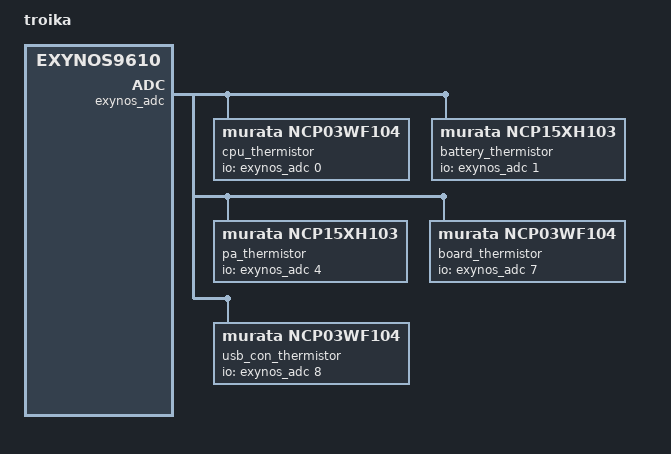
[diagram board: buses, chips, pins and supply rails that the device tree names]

/ {
	fragment@model {
		target-path = "/";
		__overlay__ {
			model = "troika";
			mot,soc-id = <0xE9610000>;
			mot,board-id = <0x43 0xA100>;

			utags {
				compatible = "mmi,utags";
				mmi,main-utags = "/dev/block/bootdevice/by-name/utags";
				mmi,backup-utags = "/dev/block/bootdevice/by-name/utagsBackup";
			};

			hw {
				compatible = "mmi,utags";
				mmi,dir-name = "hw";
				mmi,main-utags = "/dev/block/bootdevice/by-name/hw";
			};

			aov-trigger {
				status = "okay";
				compatible = "mmi,aov-trigger";
			};

		};
	};
};

&exynos_adc {
	status = "okay";
	cpu_thermistor {
		compatible = "murata,ncp03wf104";
		status = "okay";
		pullup-uv = <1800000>;
		pullup-ohm = <100000>;
		pulldown-ohm = <0>;
		io-channels = <&exynos_adc 0>;
		io-channel-names = "cpu_therm";
	};
	battery_thermistor {
		compatible = "murata,ncp15xh103";
		status = "okay";
		pullup-uv = <1800000>;
		pullup-ohm = <100000>;
		pulldown-ohm = <0>;
		io-channels = <&exynos_adc 1>;
		io-channel-names = "bat_therm";
	};
	pa_thermistor {
		compatible = "murata,ncp15xh103";
		status = "okay";
		pullup-uv = <1800000>;
		pullup-ohm = <0>;
		pulldown-ohm = <10000>;
		io-channels = <&exynos_adc 4>;
		io-channel-names = "pa_therm";
		connected-positive;
	};
	board_thermistor {
		compatible = "murata,ncp03wf104";
		status = "okay";
		pullup-uv = <1800000>;
		pullup-ohm = <100000>;
		pulldown-ohm = <0>;
		io-channels = <&exynos_adc 7>;
		io-channel-names = "board_therm";
	};
	usb_con_thermistor {
		compatible = "murata,ncp03wf104";
		status = "okay";
		pullup-uv = <1800000>;
		pullup-ohm = <100000>;
		pulldown-ohm = <0>;
		io-channels = <&exynos_adc 8>;
		io-channel-names = "usb_con_therm";
	};
};

&sar_sx933x {
		Semtech,reg-init = <
		0x8020 0x1F0000
		0x4004 0x64
		0x4008 0x00
		0x4054 0x400
		0x42C0 0x8000000
		0x42C4 0x3F
		0x800C 0x00
		0x8010 0x00
		0x8014 0x00
		0x8018 0x00
		0x801C 0x38
		0x8024 0x2000147E
		0x8028 0x3FFE8266
		0x802C 0x2000147E
		0x8030 0x3FF7825B
		0x8034 0x1000147E
		0x8038 0x3FBF8268
		0x803C 0x1000146E
		0x8040 0x3DFF825F
		0x8044 0x1000147E
		0x8048 0x2FFF82D5
		0x804C 0x88E
		0x8050 0x80001EE6
		0x8054 0x10263C15
		0x8058 0x60600031
		0x805C 0x54AC5300
		0x8060 0x00
		0x8064 0x810000
		0x8068 0x00
		0x806C 0x21002100
		0x8070 0x10000
		0x8074 0x10262915
		0x8078 0x60600031
		0x807C 0x54AC5300
		0x8080 0x00
		0x8084 0x460000
		0x8088 0x00
		0x808C 0x1E001E00
		0x8090 0x10000
		0x8094 0x1052C800
		0x8098 0x60600931
		0x809C 0x54AC4300
		0x80A0 0x00
		0x80A4 0x00
		0x80A8 0x00
		0x80AC 0x00
		0x80B0 0x00
		0x80B4 0x10223226
		0x80B8 0x60600031
		0x80BC 0x54AC5300
		0x80C0 0x00
		0x80C4 0x5C0000
		0x80C8 0x00
		0x80CC 0x400040
		0x80D0 0x20000
		0x80D4 0x1052C800
		0x80D8 0x60600931
		0x80DC 0x54AC4300
		0x80E0 0x00
		0x80E4 0x00
		0x80E8 0x00
		0x80EC 0x00
		0x80F0 0x00
		0x80F4 0x10162800
		0x80F8 0x20400031
		0x80FC 0x54AC5300
		0x8100 0x00
		0x8104 0x00
		0x8108 0x00
		0x810C 0x00
		0x8110 0x00
		0x8124 0x4000004
		0x8128 0x4000002
		0x812C 0x00
		0x8130 0x00
		0x8134 0x00
		0x8138 0x00
		0x813C 0x00
		0x8140 0x00
		0x8144 0x00
		0x8148 0x00
		0x814C 0x00
		0x81A4 0x1D40008>;
};
